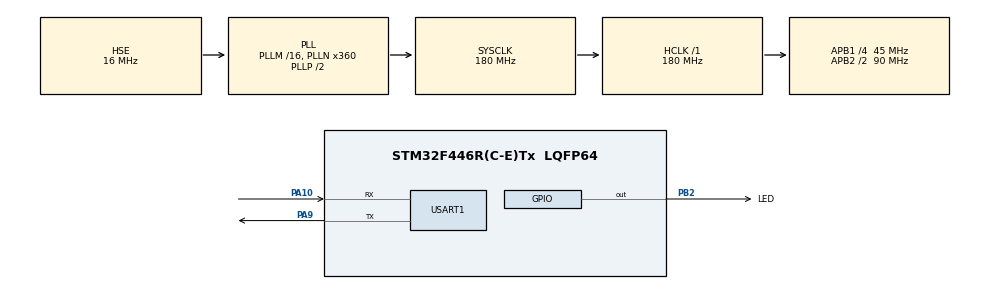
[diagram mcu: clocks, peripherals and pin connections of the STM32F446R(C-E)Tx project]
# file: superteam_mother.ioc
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Dma.Request0=USART1_RX
Dma.USART1_RX.0.Direction=DMA_PERIPH_TO_MEMORY
Dma.USART1_RX.0.FIFOMode=DMA_FIFOMODE_DISABLE
Dma.USART1_RX.0.Instance=DMA2_Stream2
Dma.USART1_RX.0.MemDataAlignment=DMA_MDATAALIGN_BYTE
Dma.USART1_RX.0.MemInc=DMA_MINC_ENABLE
Dma.USART1_RX.0.Mode=DMA_CIRCULAR
Dma.USART1_RX.0.PeriphDataAlignment=DMA_PDATAALIGN_BYTE
Dma.USART1_RX.0.PeriphInc=DMA_PINC_DISABLE
Dma.USART1_RX.0.Priority=DMA_PRIORITY_LOW
Mcu.Family=STM32F4
Mcu.Name=STM32F446R(C-E)Tx
Mcu.Package=LQFP64
NVIC.DMA2_Stream2_IRQn=true\:0\:0\:false\:false\:true\:false\:true\:true
NVIC.PriorityGroup=NVIC_PRIORITYGROUP_4
PA10.Mode=Asynchronous
PA10.Signal=USART1_RX
PA9.Mode=Asynchronous
PA9.Signal=USART1_TX
PB2.GPIO_Label=LED
PB2.Signal=GPIO_Output
PH0-OSC_IN.Mode=HSE-External-Oscillator
PH0-OSC_IN.Signal=RCC_OSC_IN
PH1-OSC_OUT.Mode=HSE-External-Oscillator
PH1-OSC_OUT.Signal=RCC_OSC_OUT
ProjectManager.HeapSize=0x200
ProjectManager.StackSize=0x400
ProjectManager.TargetToolchain=STM32CubeIDE
RCC.AHBFreq_Value=180000000
RCC.APB1CLKDivider=RCC_HCLK_DIV4
RCC.APB1Freq_Value=45000000
RCC.APB1TimFreq_Value=90000000
RCC.APB2CLKDivider=RCC_HCLK_DIV2
RCC.APB2Freq_Value=90000000
RCC.APB2TimFreq_Value=180000000
RCC.CortexFreq_Value=180000000
RCC.HCLKFreq_Value=180000000
RCC.HSE_VALUE=16000000
RCC.PLLN=360
RCC.PLLSourceVirtual=RCC_PLLSOURCE_HSE
RCC.SYSCLKFreq_VALUE=180000000
RCC.SYSCLKSource=RCC_SYSCLKSOURCE_PLLCLK
RCC.USBFreq_Value=180000000
RCC.VCOOutputFreq_Value=360000000
USART1.VirtualMode=VM_ASYNC
board=custom

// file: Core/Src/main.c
/* USER CODE BEGIN Header */
/**
  ******************************************************************************
  * @file           : main.c
  * @brief          : Main program body
  ******************************************************************************
  * @attention
  *
  * Copyright (c) 2024 STMicroelectronics.
  * All rights reserved.
  *
  * This software is licensed under terms that can be found in the LICENSE file
  * in the root directory of this software component.
  * If no LICENSE file comes with this software, it is provided AS-IS.
  *
  ******************************************************************************
  */
/* USER CODE END Header */
#include "main.h"

/* USER CODE BEGIN PD */
uint8_t rxBuf[128]={};

/* USER CODE END PD */

UART_HandleTypeDef huart1;
DMA_HandleTypeDef hdma_usart1_rx;

void SystemClock_Config(void);
static void MX_GPIO_Init(void);
static void MX_DMA_Init(void);
static void MX_USART1_UART_Init(void);

int main(void)
{

  /* MCU Configuration--------------------------------------------------------*/

  /* Reset of all peripherals, Initializes the Flash interface and the Systick. */
  HAL_Init();

  /* Configure the system clock */
  SystemClock_Config();

  /* Initialize all configured peripherals */
  MX_GPIO_Init();
  MX_DMA_Init();
  MX_USART1_UART_Init();
  /* USER CODE BEGIN 2 */
  HAL_UART_Receive_DMA(&huart1,rxBuf,128);

  /* USER CODE END 2 */

  /* Infinite loop */
  /* USER CODE BEGIN WHILE */
  while (1)
  {
	  uint8_t ledflg = 0;
	  for(int i=0; i<128; i++){
		  if(rxBuf[i] != 0){
			  ledflg == 1;
		  }
	  }
	  if(ledflg == 1){
		  HAL_GPIO_WritePin(LED_GPIO_Port, LED_Pin, GPIO_PIN_SET);
	  }else{
		  HAL_GPIO_WritePin(LED_GPIO_Port, LED_Pin, GPIO_PIN_RESET);
	  }

    /* USER CODE END WHILE */

  }
}

void SystemClock_Config(void)
{
  RCC_OscInitTypeDef RCC_OscInitStruct = {0};
  RCC_ClkInitTypeDef RCC_ClkInitStruct = {0};

  /** Configure the main internal regulator output voltage
  */
  __HAL_RCC_PWR_CLK_ENABLE();
  __HAL_PWR_VOLTAGESCALING_CONFIG(PWR_REGULATOR_VOLTAGE_SCALE1);

  /** Initializes the RCC Oscillators according to the specified parameters
  * in the RCC_OscInitTypeDef structure.
  */
  RCC_OscInitStruct.OscillatorType = RCC_OSCILLATORTYPE_HSE;
  RCC_OscInitStruct.HSEState = RCC_HSE_ON;
  RCC_OscInitStruct.PLL.PLLState = RCC_PLL_ON;
  RCC_OscInitStruct.PLL.PLLSource = RCC_PLLSOURCE_HSE;
  RCC_OscInitStruct.PLL.PLLM = 16;
  RCC_OscInitStruct.PLL.PLLN = 360;
  RCC_OscInitStruct.PLL.PLLP = RCC_PLLP_DIV2;
  RCC_OscInitStruct.PLL.PLLQ = 2;
  RCC_OscInitStruct.PLL.PLLR = 2;
  if (HAL_RCC_OscConfig(&RCC_OscInitStruct) != HAL_OK)
  {
    Error_Handler();
  }

  /** Activate the Over-Drive mode
  */
  if (HAL_PWREx_EnableOverDrive() != HAL_OK)
  {
    Error_Handler();
  }

  /** Initializes the CPU, AHB and APB buses clocks
  */
  RCC_ClkInitStruct.ClockType = RCC_CLOCKTYPE_HCLK|RCC_CLOCKTYPE_SYSCLK
                              |RCC_CLOCKTYPE_PCLK1|RCC_CLOCKTYPE_PCLK2;
  RCC_ClkInitStruct.SYSCLKSource = RCC_SYSCLKSOURCE_PLLCLK;
  RCC_ClkInitStruct.AHBCLKDivider = RCC_SYSCLK_DIV1;
  RCC_ClkInitStruct.APB1CLKDivider = RCC_HCLK_DIV4;
  RCC_ClkInitStruct.APB2CLKDivider = RCC_HCLK_DIV2;

  if (HAL_RCC_ClockConfig(&RCC_ClkInitStruct, FLASH_LATENCY_5) != HAL_OK)
  {
    Error_Handler();
  }
}

static void MX_USART1_UART_Init(void)
{

  huart1.Instance = USART1;
  huart1.Init.BaudRate = 115200;
  huart1.Init.WordLength = UART_WORDLENGTH_8B;
  huart1.Init.StopBits = UART_STOPBITS_1;
  huart1.Init.Parity = UART_PARITY_NONE;
  huart1.Init.Mode = UART_MODE_TX_RX;
  huart1.Init.HwFlowCtl = UART_HWCONTROL_NONE;
  huart1.Init.OverSampling = UART_OVERSAMPLING_16;
  if (HAL_UART_Init(&huart1) != HAL_OK)
  {
    Error_Handler();
  }

}

static void MX_DMA_Init(void)
{

  /* DMA controller clock enable */
  __HAL_RCC_DMA2_CLK_ENABLE();

  /* DMA interrupt init */
  /* DMA2_Stream2_IRQn interrupt configuration */
  HAL_NVIC_SetPriority(DMA2_Stream2_IRQn, 0, 0);
  HAL_NVIC_EnableIRQ(DMA2_Stream2_IRQn);

}

static void MX_GPIO_Init(void)
{
  GPIO_InitTypeDef GPIO_InitStruct = {0};

  /* GPIO Ports Clock Enable */
  __HAL_RCC_GPIOH_CLK_ENABLE();
  __HAL_RCC_GPIOB_CLK_ENABLE();
  __HAL_RCC_GPIOA_CLK_ENABLE();

  /*Configure GPIO pin Output Level */
  HAL_GPIO_WritePin(LED_GPIO_Port, LED_Pin, GPIO_PIN_RESET);

  /*Configure GPIO pin : LED_Pin */
  GPIO_InitStruct.Pin = LED_Pin;
  GPIO_InitStruct.Mode = GPIO_MODE_OUTPUT_PP;
  GPIO_InitStruct.Pull = GPIO_NOPULL;
  GPIO_InitStruct.Speed = GPIO_SPEED_FREQ_LOW;
  HAL_GPIO_Init(LED_GPIO_Port, &GPIO_InitStruct);

}

void Error_Handler(void)
{
  __disable_irq();
  while (1)
  {
  }
}
